# GD32E53x register map
File version: 1.0
CPU: CM33 r0p4, little endian, MPU, FPU, 4 interrupt priority bits
Registers are 32-bit, read-write, reset 0x0 unless marked. A register's access mark holds for its fields unless they carry their own. Offsets are from the block's base; [hi:lo] are bit positions; {n}, {i} and the like mark numbered series.

## DMA0 — Direct memory access controller
Base 0x40020000
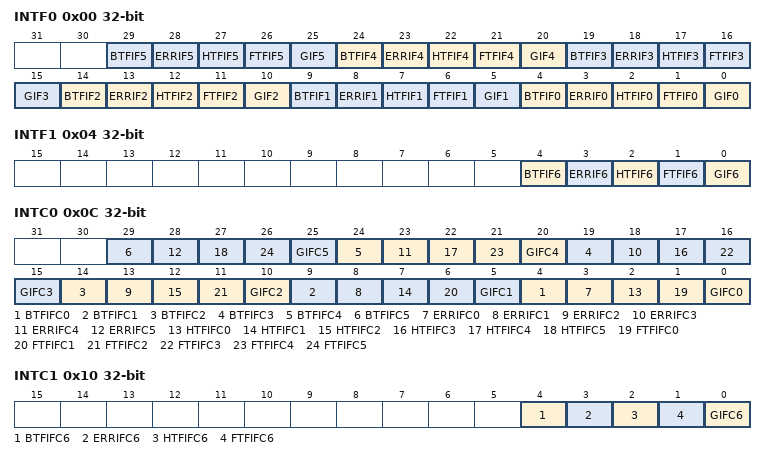
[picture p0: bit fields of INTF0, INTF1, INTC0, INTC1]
0x00 INTF0 ro — Interrupt flag register 0
  [5n+4] BTFIF{n} (n=0..5) — Block transfer finish flag of channel {n}
  [5n+3] ERRIF{n} (n=0..5) — Error flag of channel {n}
  [5n+2] HTFIF{n} (n=0..5) — Half transfer finish flag of channel {n}
  [5n+1] FTFIF{n} (n=0..5) — Full Transfer finish flag of channel {n}
  [5n] GIF{n} (n=0..5) — Global interrupt flag of channel {n}
0x04 INTF1 ro — Interrupt flag register 1
  [4] BTFIF6 — Block transfer finish flag of channel x (x=6)
  [3] ERRIF6 — Error flag of channel x (x=6)
  [2] HTFIF6 — Half transfer finish flag of channel x (x=6)
  [1] FTFIF6 — Full Transfer finish flag of channel x (x=6)
  [0] GIF6 — Global interrupt flag of channel x (x=6)
0x0C INTC0 wo — Interrupt flag clear register 0
  [5n+4] BTFIFC{n} (n=0..5) — Clear bit for block transfer finish flag of channel x (x=0...5)
  [5n+3] ERRIFC{n} (n=0..5) — Clear bit for error flag of channel x (x=0...5)
  [5n+2] HTFIFC{n} (n=0..5) — Clear bit for half transfer finish flag of channel x (x=0...5)
  [5n+1] FTFIFC{n} (n=0..5) — Clear bit for full transfer finish flag of channel x (x=0...5)
  [5n] GIFC{n} (n=0..5) — Clear global interrupt flag of channel x (x=0...5)
0x10 INTC1 wo — Interrupt flag clear register 1
  [4] BTFIFC6 — Clear bit for block transfer finish flag of channel x (x=6)
  [3] ERRIFC6 — Clear bit for error flag of channel x (x=6)
  [2] HTFIFC6 — Clear bit for half transfer finish flag of channel x (x=6)
  [1] FTFIFC6 — Clear bit for full transfer finish flag of channel x (x=6)
  [0] GIFC6 — Clear global interrupt flag of channel x (x=6)
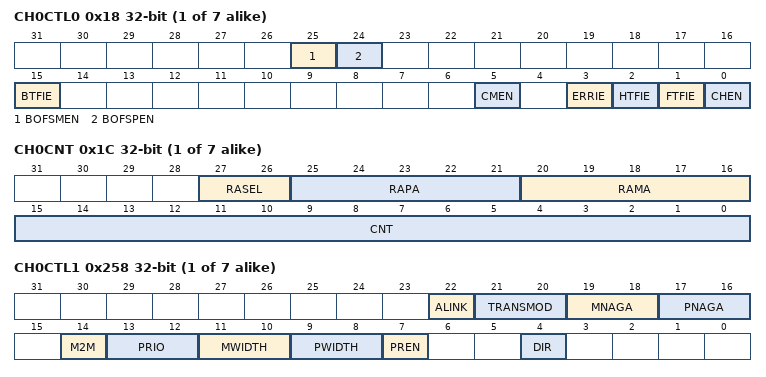
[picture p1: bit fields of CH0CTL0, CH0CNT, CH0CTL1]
{0x18+0x10*i} CH{i}CTL0 (i=0..6) — Channel {i} control register
  [25] BOFSMEN — Enable memory block offset
  [24] BOFSPEN — Block peripheral offset enable
  [15] BTFIE — Enable bit for Block transfer finish interrupt
  [5] CMEN — Circular mode enable
  [3] ERRIE — Enable bit for channel error interrupt
  [2] HTFIE — Enable bit for channel half transfer finish interrupt
  [1] FTFIE — Enable bit for channel full transfer finish interrupt
  [0] CHEN — Channel enable
{0x1C+0x10*i} CH{i}CNT (i=0..6) — Channel {i} counter regist
  [27:26] RASEL — Repeat area selection
  [25:21] RAPA — Repeat area of peripheral address
  [20:16] RAMA — Repeat area of memory address
  [15:0] CNT — Transfer counter
{0x20+0x10*i} CH{i}PADDR (i=0..6) — Channel {i} peripheral base address regist
  [31:0] PADDR — Peripheral base address
{0x24+0x10*i} CH{i}MADDR (i=0..6) — Channel {i} memory base address regist
  [31:0] MADDR — Memory base address
0x118 CH0PAOFS — Channel 0 peripheral address offset register
  [31:0] PAOFS — Paddr offset value when PNAGA is 11.
0x11C CH0MAOFS — Channel 0 memory address offset register
  [31:0] MAOFS — Maddr offset value when MNAGA is 11
{0x120+8i} CH{i}LADDR (i=0..6) — Channel {i} link-list address regist
  [31:0] LADDR — The descriptor address in link-list mode
{0x124+8i} CH{i}BCNT (i=0..6) — Channel {i} block cnounter regist
  [15:0] BCNT — The block numer of DMA transferred is BCNT[15:0] + 1.
{0x1D8+8i} CH{i}PABOFS (i=0..6) — Channel {i} peripheral block offset regist
  [31:0] PABOFS — PADDR offset value between blocks when BOFSPEN is 1.
{0x1DC+8i} CH{i}MABOFS (i=0..6) — Channel {i} memory block offset regist
  [31:0] MABOFS — MADDR offset value between blocks
{0x258+4i} CH{i}CTL1 (i=0..6) — Channel {i} control1 regist
  [22] ALINK — Automatically flip to the next descriptor enable
  [21:20] TRANSMOD — The data transfer mode
  [19:18] MNAGA — Next address generation algorithm of memory
  [17:16] PNAGA — Next address generation algorithm of peripheral
  [14] M2M — Memory to Memory mode
  [13:12] PRIO — Priority level
  [11:10] MWIDTH — Transfer data size of memory
  [9:8] PWIDTH — Transfer data size of peripheral
  [7] PREN — Preemption enable
  [4] DIR — Transfer direction

## DMA1 — Direct memory access controller
Base 0x40020400
Registers as DMA0, without INTF1, INTC1, CH5CTL0, CH5CNT, CH5PADDR, CH5MADDR, CH6CTL0, CH6CNT, CH6PADDR, CH6MADDR, CH5LADDR, CH5BCNT, CH6LADDR, CH6BCNT, CH5PABOFS, CH5MABOFS, CH6PABOFS, CH6MABOFS, CH5CTL1, CH6CTL1; these are added or differ:
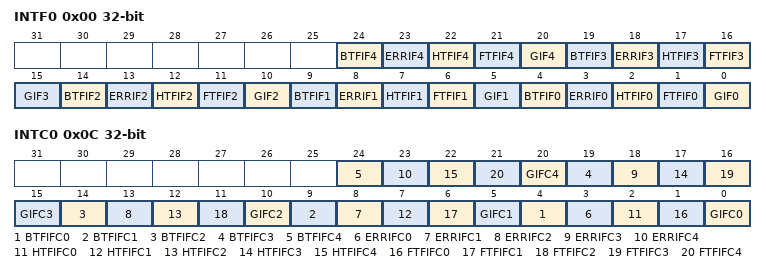
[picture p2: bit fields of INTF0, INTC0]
0x00 INTF0 ro — Interrupt flag register 0
  [5n+4] BTFIF{n} (n=0..4) — Block transfer finish flag of channel {n}
  [5n+3] ERRIF{n} (n=0..4) — Error flag of channel {n}
  [5n+2] HTFIF{n} (n=0..4) — Half transfer finish flag of channel {n}
  [5n+1] FTFIF{n} (n=0..4) — Full Transfer finish flag of channel {n}
  [5n] GIF{n} (n=0..4) — Global interrupt flag of channel {n}
0x0C INTC0 wo — Interrupt flag clear register 0
  [5n+4] BTFIFC{n} (n=0..4) — Clear bit for block transfer finish flag of channel x (x=0...4)
  [5n+3] ERRIFC{n} (n=0..4) — Clear bit for error flag of channel x (x=0...4)
  [5n+2] HTFIFC{n} (n=0..4) — Clear bit for half transfer finish flag of channel x (x=0...4)
  [5n+1] FTFIFC{n} (n=0..4) — Clear bit for full transfer finish flag of channel x (x=0...4)
  [5n] GIFC{n} (n=0..4) — Clear global interrupt flag of channel x (x=0...4)
